# ECM3532 register map
Vendor: EtaCompute; Series: ECM35xx; File version: 1.0.0
CPU: CM3 r1p1, little endian, MPU, no FPU, 3 interrupt priority bits
Registers are 32-bit, read-write, reset 0x0 unless marked. A register's access mark holds for its fields unless they carry their own. Offsets are from the block's base; [hi:lo] are bit positions; {n}, {i} and the like mark numbered series.

## GPIO — The General Purpose I/O (GPIO) Device provides programmable access to the pins of the chip from within the M3 complex.
Base 0x40010000
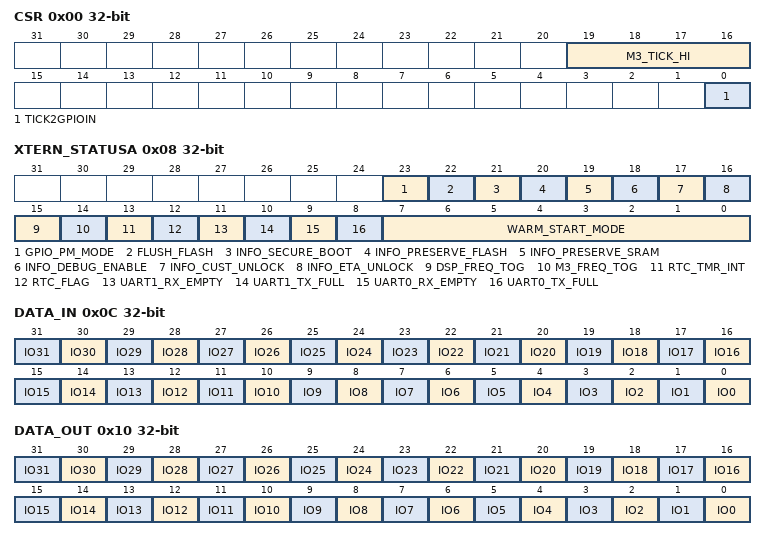
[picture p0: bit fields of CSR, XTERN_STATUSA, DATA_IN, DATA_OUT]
0x00 CSR — Control and Status Register for GPIO inside of M3 Complex.
  [19:16] M3_TICK_HI ro — The M3 TICK counter is 36 bits long. The upper 4 bits, M3_TICK[35:32], can be read here when the counter is frozen.
  [0] TICK2GPIOIN — Enable a few clock sources as inputs for GPIO[7:0] instead of the usual pad inputs. This assumes these GPIOs are normally used as outputs to drive LEDs on a board. This allow these bits to simultaneously serve as dedicated outputs and also as dedicated inputs.
    1=ENABLE (Enable ticks to GPIO inputs.); 0=DISABLE (Do not use the tick inputs.)
0x04 M3_TICK — This register accumulates tick counts at the rate of the M3 oscillator. Firmware controls when it starts counting and when it stops counting. It is intended to measure the duration of firmware execution regions in core (M3) oscillator ticks.
  [31:0] COUNT ro — This register accumulates tick counts at the rate of the M3 oscillator. Firmware first issues a start command, which clears the count and then begins counting up. Firmware then issues a stop command which freezes the count so it can be read. Write 0x474F to clear and restart the counter. Write 0x4E4F to freeze the count. Write 0xAAAA to resume counting where it left off.
    0x474F=CLEAR_AND_START (First clear the counter and then begin counting M3 oscillator ticks.); 0x4E4F=FREEZE (Freeze the counter so it can be read.); 0xAAAA=RESUME (Resume counting from where it was stopped.)
0x08 XTERN_STATUSA — Quick read of various external status bits.
  [23] GPIO_PM_MODE ro — This read only bit indicates the state of the GPIO PM MODE pin. If it is one then bootrom firmware must check GPIO[28]. If that is zero then bootrom firmware has to decde GPIO[31:29].
    0=NORMAL (Perform normal customer facing bootmode.); 1=VALIDATION (Select validdation bootmode from GPIO[31:29], provided GPIO[28] == zero.)
  [22] FLUSH_FLASH ro — This read only bit indicates that a debugger has been detected on the SWD interface while INFO page indicates that the FLASH is not to be preserved in this case. This bit is used in the boot ROM.
  [21] INFO_SECURE_BOOT ro — This read only bit indicates that a secure boot protocol will be used at power up to provide a hardware root of trust state for the code to be executed in flash segment zero.
  [20] INFO_PRESERVE_FLASH ro — This read only bit indicates that the FLASH will be preserved when a debugger is attached to the SWD port. Zero indiates that it will be erased when a debugger is attached to hide the contents from view.
  [19] INFO_PRESERVE_SRAM ro — This read only bit indicates that the SRAM will be preserved when a debugger is attached to the SWD port. Zero indiates that it will be erased when a debugger is attached to hide the contents from view.
  [18] INFO_DEBUG_ENABLE ro — This read only bit indicates whether the SWD port is enabled for debug. Zero indiates that a debugger can not be connected through the SWD port.
  [17] INFO_CUST_UNLOCK ro — This read only bit indicates whether the customer section of the INFO page is unlocked for further programming. This is represents the state for the last 3072 bytes in the INFO page. If this bit is set to zero then INFO page can not be erased.
  [16] INFO_ETA_UNLOCK ro — This read only bit indicates whether the Eta Compute section of the INFO page is unlocked for further programming. This is represents the state for the first 1024 bytes in the INFO page. If this bit is set to zero then INFO page can not be erased.
  [15] DSP_FREQ_TOG ro — A toggle on this read only bit indicates that the DSP frequency counter has produced a fresh value.
  [14] M3_FREQ_TOG ro — A toggle on this read only bit indicates that the M3 frequency counter has produced a fresh value.
  [13] RTC_TMR_INT ro — This read only bit provides access to the RTC TIMER interrupt status bit.
  [12] RTC_FLAG ro — This read only bit toggles everytime the RTC time of day counter increments (once per second). It is used to guarantee safe reads of the current time of day.
  [11] UART1_RX_EMPTY ro — This read only bit tells driver level code whent there is at least one byte to the UART1 receiver FIFO.
  [10] UART1_TX_FULL ro — This read only bit tells driver level code whent there is room to add at least one more byte to the UART1 transmitter FIFO.
  [9] UART0_RX_EMPTY ro — This read only bit tells driver level code whent there is at least one byte to the UART0 receiver FIFO.
  [8] UART0_TX_FULL ro — This read only bit tells driver level code whent there is room to add at least one more byte to the UART0 transmitter FIFO.
  [7:0] WARM_START_MODE ro — These read only bits tell the BOOTROM how to warm start and if it should warm start. Anything greater than 0x8 is a warm start.
    0=NORMAL_COLD_START (Normal cold start in SRAM or flash.); 1=FORCE_COLD_START_IN_FLASH (Force cold start in flash even if valid SRAM program present.)
0x0C DATA_IN — Data INPUT for each PAD.
  [n] IO{n} ro (n=0..31) — Input bits from each Pad/Pin
0x10 DATA_OUT — Data Output for each PAD.
  [n] IO{n} (n=0..31) — Set or clear output bit
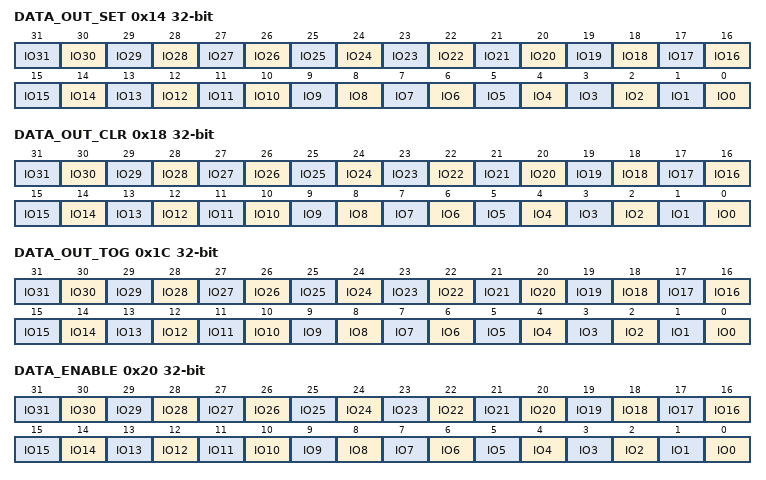
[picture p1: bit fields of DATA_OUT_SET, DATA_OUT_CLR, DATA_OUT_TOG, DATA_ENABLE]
0x14 DATA_OUT_SET — Set 1 to set Data Output to one.
  [n] IO{n} wo (n=0..31) — Set to 1 to set output bit
0x18 DATA_OUT_CLR — Set 1 to set Data Output to zero.
  [n] IO{n} wo (n=0..31) — Set to 1 to clear output bit
0x1C DATA_OUT_TOG — Set 1 to toggle Data Output to zero.
  [n] IO{n} wo (n=0..31) — Set to 1 toggle output bit
0x20 DATA_ENABLE — Data Output Enable for each PAD.
  [n] IO{n} (n=0..31) — Set to 1 to enable output bit
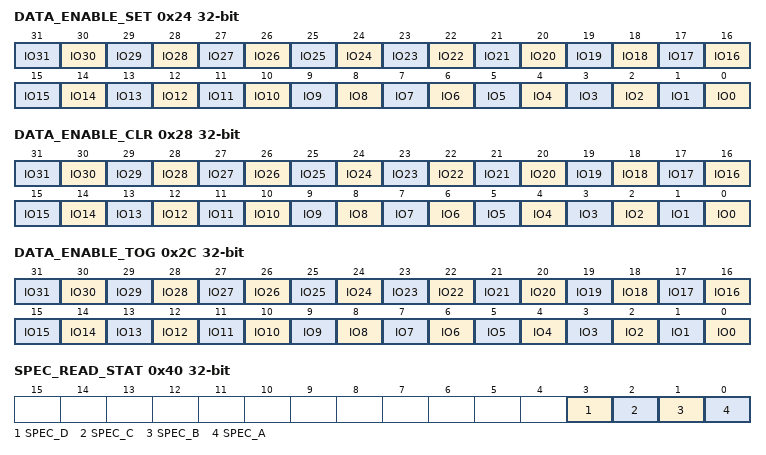
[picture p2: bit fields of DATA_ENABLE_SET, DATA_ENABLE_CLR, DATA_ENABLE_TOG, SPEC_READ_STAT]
0x24 DATA_ENABLE_SET — Set Data Output Enable for each PAD.
  [n] IO{n} wo (n=0..31) — Set to 1 to set enable output bit
0x28 DATA_ENABLE_CLR — Clear Data Output Enable for each PAD.
  [n] IO{n} wo (n=0..31) — Set to 1 to clr enable output bit
0x2C DATA_ENABLE_TOG — Toggle Data Output Enable for each PAD.
  [n] IO{n} wo (n=0..31) — Set to 1 toggle enable output bit
0x30 SPEC_READ_A — Provide a read only value for speculative read support on the peripheral bus.
  [31:0] VALUE ro — Read Only Value of a speculative read.
0x34 SPEC_READ_B — Provide a read only value for speculative read support on the peripheral bus.
  [31:0] VALUE ro — Read Only Value of a speculative read.
0x38 SPEC_READ_C — Provide a read only value for speculative read support on the peripheral bus.
  [31:0] VALUE ro — Read Only Value of a speculative read.
0x3C SPEC_READ_D — Provide a read only value for speculative read support on the peripheral bus.
  [31:0] VALUE ro — Read Only Value of a speculative read.
0x40 SPEC_READ_STAT — Provide a status bit for each of the four speculative read contexts.
  [all] fields
    1=READY (Result is ready.)
  [3] SPEC_D — Speculative read data available for read. Write a one to this bit to clear it.
  [2] SPEC_C — Speculative read data available for read. Write a one to this bit to clear it.
  [1] SPEC_B — Speculative read data available for read. Write a one to this bit to clear it.
  [0] SPEC_A — Speculative read data available for read. Write a one to this bit to clear it.
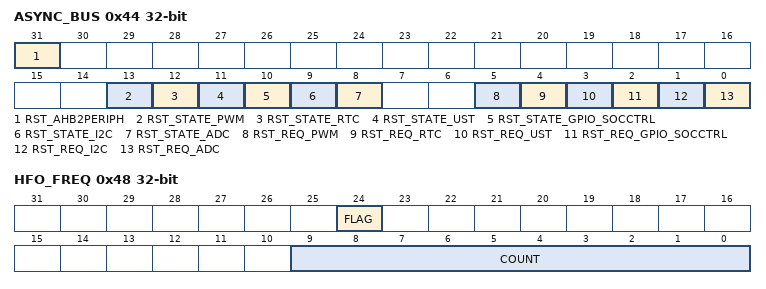
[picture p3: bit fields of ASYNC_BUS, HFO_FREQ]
0x44 ASYNC_BUS — Control fields for the asynchronous buses.
  [31] RST_AHB2PERIPH wo — Flush the buffer and reset the state of the AHB2PERIPH logic. This will also issue a reset request on all async buses.
    1=RESET (Assert the reset.)
  [13] RST_STATE_PWM ro — Actual reset response from the slave.
    0=RESET (Slave reset); 1=ACTIVE (Slave active)
  [12] RST_STATE_RTC ro — Actual reset response from the slave
    0=RESET (Slave reset); 1=ACTIVE (Slave active)
  [11] RST_STATE_UST ro — Actual reset response from the slave
    0=RESET (Slave reset); 1=ACTIVE (Slave active)
  [10] RST_STATE_GPIO_SOCCTRL ro — Actual reset response from the slave.
    0=RESET (Slave reset); 1=ACTIVE (Slave active)
  [9] RST_STATE_I2C ro — Actual reset response from the slave.
    0=RESET (Slave reset); 1=ACTIVE (Slave active)
  [8] RST_STATE_ADC ro — Actual reset response from the slave.
    0=RESET (Slave reset); 1=ACTIVE (Slave active)
  [5] RST_REQ_PWM — Issue a reset request from the PWM async bus master. Field will remain set until reset is complete.
    1=RESET (Assert the reset request.)
  [4] RST_REQ_RTC — Issue a reset request from the RTC async bus master. Field will remain set until reset is complete.
    1=RESET (Assert the reset request.)
  [3] RST_REQ_UST — Issue a reset request from the UST async bus master. Field will remain set until reset is complete.
    1=RESET (Assert the reset request.)
  [2] RST_REQ_GPIO_SOCCTRL — Issue a reset request from the GPIO/SOCCTRL async bus master. Field will remain set until reset is complete.
    1=RESET (Assert the reset request.)
  [1] RST_REQ_I2C — Issue a reset request from the I2C async bus master. Field will remain set until reset is complete.
    1=RESET (Assert the reset request.)
  [0] RST_REQ_ADC — Issue a reset request from the ADC async bus master. Field will remain set until reset is complete.
    1=RESET (Assert the reset request.)
0x48 HFO_FREQ — This register contains the frequency counter for the HFO. It counts the number of HFO clocks that occur between two rising edges of the 32KHz clock. NOTE: while this counter measures for the period of one 32KHz clock it does not do it every clock. This register will update every 4 32KHz clocks.
  [24] FLAG ro — This toggles for every counter update (once every 4x32KHz clocks).
  [9:0] COUNT ro — This counter tells the approximate frequency of the HFO.
0x4C FLASH_INFO_RD_ENABLE — Provide a read only view of the flash read protection word obtained from the flash INFO page during POR sequencing. This value is saved in AO and restored at each subsequent M3 power up event even though the FLASH may have been forced off at power up. Thus these protections exist from before reset is removed from the M3 until it is powered down. Each bit in this register corresponds to one 16KB segment in flash.
  [31:0] VALUE ro — When a bit is set to zero then the corresponding 16KB segment in flash is read protected. Neither the M3 nor the DSP can read a value from the affected segment. It can be fetched for execution but not loaded into a register. This also applies to attempts from a debugger to read the value.
0x50 FLASH_INFO_WRT_ENABLE — Provide a read only view of the flash write protection word obtained from the flash INFO page during POR sequencing. This value is saved in AO and restored at each subsequent M3 power up event even though the FLASH may have been forced off at power up. Thus these protections exist from before reset is removed from the M3 until it is powered down. Each bit in this register corresponds to one 16KB segment in flash.
  [31:0] VALUE ro — When a bit is set to zero then the corresponding 16KB segment in flash is write protected. The flash controller will will not allow any page in the segment to be erased or programmd.
0x54 DEBUG0_READ_ONLY — Provide a read only value for diagnostics.
  [31:0] VALUE ro — Debug Read Only Value for Diagnostics.
0x58 DEBUG1_READ_ONLY — Provide a read only value for diagnostics.
  [31:0] VALUE ro — Debug Read Only Value for Diagnostics.
